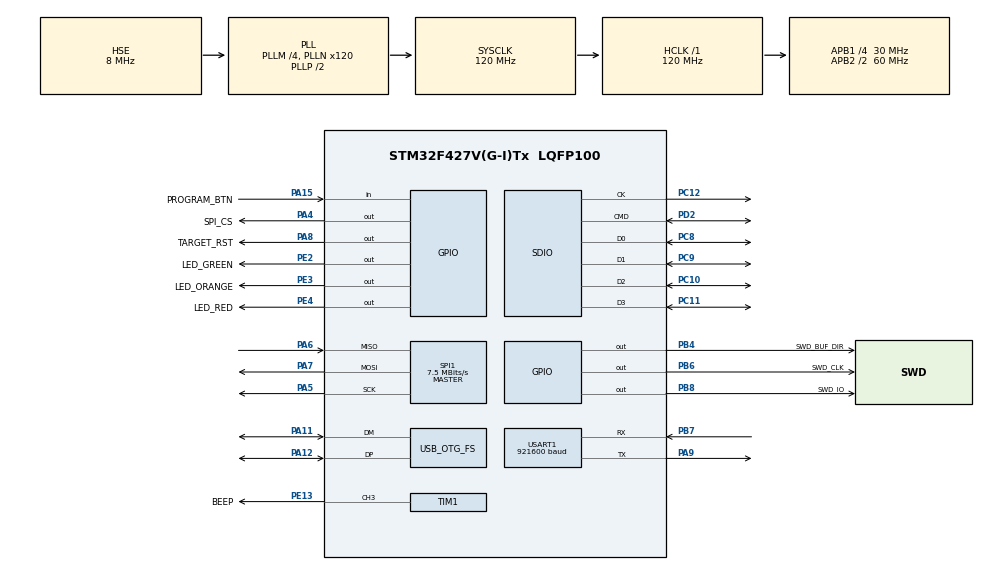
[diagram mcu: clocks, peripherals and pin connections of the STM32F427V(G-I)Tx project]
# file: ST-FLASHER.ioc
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Dma.Request0=SDIO_RX
Dma.Request1=SDIO_TX
Dma.SDIO_RX.0.Direction=DMA_PERIPH_TO_MEMORY
Dma.SDIO_RX.0.FIFOMode=DMA_FIFOMODE_ENABLE
Dma.SDIO_RX.0.FIFOThreshold=DMA_FIFO_THRESHOLD_FULL
Dma.SDIO_RX.0.Instance=DMA2_Stream3
Dma.SDIO_RX.0.MemBurst=DMA_MBURST_INC4
Dma.SDIO_RX.0.MemDataAlignment=DMA_MDATAALIGN_WORD
Dma.SDIO_RX.0.MemInc=DMA_MINC_ENABLE
Dma.SDIO_RX.0.Mode=DMA_PFCTRL
Dma.SDIO_RX.0.PeriphBurst=DMA_PBURST_INC4
Dma.SDIO_RX.0.PeriphDataAlignment=DMA_PDATAALIGN_WORD
Dma.SDIO_RX.0.PeriphInc=DMA_PINC_DISABLE
Dma.SDIO_RX.0.Priority=DMA_PRIORITY_LOW
Dma.SDIO_TX.1.Direction=DMA_MEMORY_TO_PERIPH
Dma.SDIO_TX.1.FIFOMode=DMA_FIFOMODE_ENABLE
Dma.SDIO_TX.1.FIFOThreshold=DMA_FIFO_THRESHOLD_FULL
Dma.SDIO_TX.1.Instance=DMA2_Stream6
Dma.SDIO_TX.1.MemBurst=DMA_MBURST_INC4
Dma.SDIO_TX.1.MemDataAlignment=DMA_MDATAALIGN_WORD
Dma.SDIO_TX.1.MemInc=DMA_MINC_ENABLE
Dma.SDIO_TX.1.Mode=DMA_PFCTRL
Dma.SDIO_TX.1.PeriphBurst=DMA_PBURST_INC4
Dma.SDIO_TX.1.PeriphDataAlignment=DMA_PDATAALIGN_WORD
Dma.SDIO_TX.1.PeriphInc=DMA_PINC_DISABLE
Dma.SDIO_TX.1.Priority=DMA_PRIORITY_LOW
FATFS.USE_DMA_CODE_SD=1
FATFS._FS_TIMEOUT=5000
FATFS._USE_LFN=2
Mcu.Family=STM32F4
Mcu.Name=STM32F427V(G-I)Tx
Mcu.Package=LQFP100
NVIC.DMA2_Stream3_IRQn=true\:6\:0\:true\:false\:true\:false\:true\:true
NVIC.DMA2_Stream6_IRQn=true\:6\:0\:true\:false\:true\:false\:true\:true
NVIC.OTG_FS_IRQn=true\:7\:0\:true\:false\:true\:true\:true\:true
NVIC.PriorityGroup=NVIC_PRIORITYGROUP_4
NVIC.SDIO_IRQn=true\:5\:0\:true\:false\:true\:true\:true\:true
NVIC.TIM1_UP_TIM10_IRQn=true\:0\:0\:false\:false\:true\:true\:true\:true
NVIC.TIM2_IRQn=true\:0\:0\:false\:false\:true\:true\:true\:true
PA11.Mode=Device_Only
PA11.Signal=USB_OTG_FS_DM
PA12.Mode=Device_Only
PA12.Signal=USB_OTG_FS_DP
PA13.Mode=Serial_Wire
PA13.Signal=SYS_JTMS-SWDIO
PA14.Mode=Serial_Wire
PA14.Signal=SYS_JTCK-SWCLK
PA15.GPIO_Label=PROGRAM_BTN
PA15.Signal=GPIO_Input
PA4.GPIO_Label=SPI_CS
PA4.Signal=GPIO_Output
PA5.Mode=Full_Duplex_Master
PA5.Signal=SPI1_SCK
PA6.GPIO_PuPd=GPIO_PULLUP
PA6.Mode=Full_Duplex_Master
PA6.Signal=SPI1_MISO
PA7.Mode=Full_Duplex_Master
PA7.Signal=SPI1_MOSI
PA8.GPIO_Label=TARGET_RST
PA8.Signal=GPIO_Output
PA9.Mode=Asynchronous
PA9.Signal=USART1_TX
PB4.GPIO_Label=SWD_BUF_DIR
PB4.GPIO_PuPd=GPIO_PULLUP
PB4.GPIO_Speed=GPIO_SPEED_FREQ_VERY_HIGH
PB4.Signal=GPIO_Output
PB6.GPIO_Label=SWD_CLK
PB6.GPIO_PuPd=GPIO_PULLDOWN
PB6.GPIO_Speed=GPIO_SPEED_FREQ_VERY_HIGH
PB6.PinState=GPIO_PIN_SET
PB6.Signal=GPIO_Output
PB7.Mode=Asynchronous
PB7.Signal=USART1_RX
PB8.GPIO_Label=SWD_IO
PB8.GPIO_PuPd=GPIO_PULLUP
PB8.GPIO_Speed=GPIO_SPEED_FREQ_VERY_HIGH
PB8.PinState=GPIO_PIN_RESET
PB8.Signal=GPIO_Output
PC10.GPIO_PuPd=GPIO_PULLUP
PC10.Mode=SD_4_bits_Wide_bus
PC10.Signal=SDIO_D2
PC11.GPIO_PuPd=GPIO_PULLUP
PC11.Mode=SD_4_bits_Wide_bus
PC11.Signal=SDIO_D3
PC12.GPIO_PuPd=GPIO_NOPULL
PC12.Mode=SD_4_bits_Wide_bus
PC12.Signal=SDIO_CK
PC8.GPIO_PuPd=GPIO_PULLUP
PC8.Mode=SD_4_bits_Wide_bus
PC8.Signal=SDIO_D0
PC9.GPIO_PuPd=GPIO_PULLUP
PC9.Mode=SD_4_bits_Wide_bus
PC9.Signal=SDIO_D1
PD2.GPIO_PuPd=GPIO_PULLUP
PD2.Mode=SD_4_bits_Wide_bus
PD2.Signal=SDIO_CMD
PE13.GPIO_Label=BEEP
PE13.GPIO_Speed=GPIO_SPEED_FREQ_VERY_HIGH
PE13.Signal=S_TIM1_CH3
PE2.GPIO_Label=LED_GREEN
PE2.PinState=GPIO_PIN_SET
PE2.Signal=GPIO_Output
PE3.GPIO_Label=LED_ORANGE
PE3.PinState=GPIO_PIN_SET
PE3.Signal=GPIO_Output
PE4.GPIO_Label=LED_RED
PE4.PinState=GPIO_PIN_SET
PE4.Signal=GPIO_Output
PH0/OSC_IN.Mode=HSE-External-Oscillator
PH0/OSC_IN.Signal=RCC_OSC_IN
PH1/OSC_OUT.Mode=HSE-External-Oscillator
PH1/OSC_OUT.Signal=RCC_OSC_OUT
ProjectManager.HeapSize=0x2000
ProjectManager.StackSize=0x2000
ProjectManager.TargetToolchain=STM32CubeIDE
RCC.48MHZClocksFreq_Value=48000000
RCC.AHBFreq_Value=120000000
RCC.APB1CLKDivider=RCC_HCLK_DIV4
RCC.APB1Freq_Value=30000000
RCC.APB1TimFreq_Value=60000000
RCC.APB2CLKDivider=RCC_HCLK_DIV2
RCC.APB2Freq_Value=60000000
RCC.APB2TimFreq_Value=120000000
RCC.CortexFreq_Value=120000000
RCC.HCLKFreq_Value=120000000
RCC.HSE_VALUE=8000000
RCC.HSI_VALUE=16000000
RCC.LSE_VALUE=32768
RCC.LockedElements=USBOTGOutput,PeriphPrescOutput,TimPrescOut,APB1Output,APB2Output
RCC.PLLM=4
RCC.PLLN=120
RCC.PLLQ=5
RCC.RCC_RTC_Clock_SourceVirtual=RCC_RTCCLKSOURCE_HSE_DIV8
RCC.RCC_RTC_Clock_Source_FROM_HSE=RCC_RTCCLKSOURCE_HSE_DIV8
RCC.SYSCLKFreq_VALUE=120000000
RCC.SYSCLKSource=RCC_SYSCLKSOURCE_PLLCLK
RCC.VCOOutputFreq_Value=240000000
RTC.AsynchPrediv=127
RTC.SynchPrediv=7874
SH.S_TIM1_CH3.0=TIM1_CH3,PWM Generation3 CH3
SPI1.BaudRatePrescaler=SPI_BAUDRATEPRESCALER_8
SPI1.CalculateBaudRate=7.5 MBits/s
SPI1.Direction=SPI_DIRECTION_2LINES
SPI1.Mode=SPI_MODE_MASTER
SPI1.VirtualType=VM_MASTER
TIM1.Channel-PWM\ Generation3\ CH3=TIM_CHANNEL_3
TIM1.Period=1000
TIM1.Prescaler=120-1
TIM2.Period=65535
TIM2.Prescaler=60-1
USART1.BaudRate=921600
USART1.Mode=MODE_TX
USART1.VirtualMode=VM_ASYNC
USB_DEVICE.CLASS_NAME_FS=MSC
USB_DEVICE.USBD_DEBUG_LEVEL-MSC_FS=3
USB_DEVICE.USBD_SELF_POWERED-MSC_FS=0
USB_DEVICE.VirtualMode-MSC_FS=Msc
USB_DEVICE.VirtualModeFS=Msc_FS
USB_OTG_FS.VirtualMode=Device_Only
VP_FATFS_VS_SDIO.Mode=SDIO
VP_RTC_VS_RTC_Activate.Mode=RTC_Enabled
VP_TIM1_VS_ClockSourceINT.Mode=Internal
VP_TIM2_VS_ClockSourceINT.Mode=Internal
VP_USB_DEVICE_VS_USB_DEVICE_MSC_FS.Mode=MSC_FS
board=custom

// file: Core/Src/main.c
/* USER CODE BEGIN Header */
/**
  ******************************************************************************
  * @file           : main.c
  * @brief          : Main program body
  ******************************************************************************
  * @attention
  *
  * Copyright (c) 2024 STMicroelectronics.
  * All rights reserved.
  *
  * This software is licensed under terms that can be found in the LICENSE file
  * in the root directory of this software component.
  * If no LICENSE file comes with this software, it is provided AS-IS.
  *
  ******************************************************************************
  */
/* USER CODE END Header */
#include "main.h"
#include "fatfs.h"
#include "usb_device.h"

/* USER CODE BEGIN Includes */
#include "Target.h"
#include "led.h"
#include "buzzer.h"

/* USER CODE END Includes */

RTC_HandleTypeDef hrtc;

SD_HandleTypeDef hsd;
DMA_HandleTypeDef hdma_sdio_rx;
DMA_HandleTypeDef hdma_sdio_tx;

SPI_HandleTypeDef hspi1;

TIM_HandleTypeDef htim1;
TIM_HandleTypeDef htim2;

UART_HandleTypeDef huart1;

void SystemClock_Config(void);
static void MX_GPIO_Init(void);
static void MX_DMA_Init(void);
static void MX_SDIO_SD_Init(void);
static void MX_TIM1_Init(void);
static void MX_TIM2_Init(void);
static void MX_SPI1_Init(void);
static void MX_USART1_UART_Init(void);
static void MX_RTC_Init(void);

int main(void)
{

  /* MCU Configuration--------------------------------------------------------*/

  /* Reset of all peripherals, Initializes the Flash interface and the Systick. */
   HAL_Init();

  /* Configure the system clock */
  SystemClock_Config();

  /* Initialize all configured peripherals */
  MX_GPIO_Init();
  MX_DMA_Init();
  MX_SDIO_SD_Init();
  MX_TIM1_Init();
  MX_TIM2_Init();
  MX_SPI1_Init();
  MX_USART1_UART_Init();
  MX_FATFS_Init();
  MX_USB_DEVICE_Init();
  MX_RTC_Init();
  /* USER CODE BEGIN 2 */

	/* SWD DAP usDelay(): TIM1 */
	HAL_TIM_Base_Start(&htim2);

	/* Set programmer LED & Buzzer state */
	LED_SetState(TARGET_LED_STAT_BOOT);
	Buzzer_SetState(BUZZER_BOOT);

	log_message("ST-FLASHER Boot OK! %s\n", PROJECT_VERSION);
	log_message("%s\n", BUILD_INFO);

  /* USER CODE END 2 */

  /* Infinite loop */
  while (1)
  {

    /* USER CODE BEGIN 3 */
  	Target_MainLoop();
  }
  /* USER CODE END 3 */
}

void SystemClock_Config(void)
{
  RCC_OscInitTypeDef RCC_OscInitStruct = {0};
  RCC_ClkInitTypeDef RCC_ClkInitStruct = {0};

  /** Configure the main internal regulator output voltage
  */
  __HAL_RCC_PWR_CLK_ENABLE();
  __HAL_PWR_VOLTAGESCALING_CONFIG(PWR_REGULATOR_VOLTAGE_SCALE3);

  /** Initializes the RCC Oscillators according to the specified parameters
  * in the RCC_OscInitTypeDef structure.
  */
  RCC_OscInitStruct.OscillatorType = RCC_OSCILLATORTYPE_HSE;
  RCC_OscInitStruct.HSEState = RCC_HSE_ON;
  RCC_OscInitStruct.PLL.PLLState = RCC_PLL_ON;
  RCC_OscInitStruct.PLL.PLLSource = RCC_PLLSOURCE_HSE;
  RCC_OscInitStruct.PLL.PLLM = 4;
  RCC_OscInitStruct.PLL.PLLN = 120;
  RCC_OscInitStruct.PLL.PLLP = RCC_PLLP_DIV2;
  RCC_OscInitStruct.PLL.PLLQ = 5;
  if (HAL_RCC_OscConfig(&RCC_OscInitStruct) != HAL_OK)
  {
    Error_Handler();
  }

  /** Initializes the CPU, AHB and APB buses clocks
  */
  RCC_ClkInitStruct.ClockType = RCC_CLOCKTYPE_HCLK|RCC_CLOCKTYPE_SYSCLK
                              |RCC_CLOCKTYPE_PCLK1|RCC_CLOCKTYPE_PCLK2;
  RCC_ClkInitStruct.SYSCLKSource = RCC_SYSCLKSOURCE_PLLCLK;
  RCC_ClkInitStruct.AHBCLKDivider = RCC_SYSCLK_DIV1;
  RCC_ClkInitStruct.APB1CLKDivider = RCC_HCLK_DIV4;
  RCC_ClkInitStruct.APB2CLKDivider = RCC_HCLK_DIV2;

  if (HAL_RCC_ClockConfig(&RCC_ClkInitStruct, FLASH_LATENCY_3) != HAL_OK)
  {
    Error_Handler();
  }
}

static void MX_RTC_Init(void)
{

  /** Initialize RTC Only
  */
  hrtc.Instance = RTC;
  hrtc.Init.HourFormat = RTC_HOURFORMAT_24;
  hrtc.Init.AsynchPrediv = 127;
  hrtc.Init.SynchPrediv = 7874;
  hrtc.Init.OutPut = RTC_OUTPUT_DISABLE;
  hrtc.Init.OutPutPolarity = RTC_OUTPUT_POLARITY_HIGH;
  hrtc.Init.OutPutType = RTC_OUTPUT_TYPE_OPENDRAIN;
  if (HAL_RTC_Init(&hrtc) != HAL_OK)
  {
    Error_Handler();
  }

}

static void MX_SDIO_SD_Init(void)
{

  hsd.Instance = SDIO;
  hsd.Init.ClockEdge = SDIO_CLOCK_EDGE_RISING;
  hsd.Init.ClockBypass = SDIO_CLOCK_BYPASS_DISABLE;
  hsd.Init.ClockPowerSave = SDIO_CLOCK_POWER_SAVE_DISABLE;
  hsd.Init.BusWide = SDIO_BUS_WIDE_4B;
  hsd.Init.HardwareFlowControl = SDIO_HARDWARE_FLOW_CONTROL_DISABLE;
  hsd.Init.ClockDiv = 0;
  /* USER CODE BEGIN SDIO_Init 2 */

  /* I don't know why... */
  hsd.Init.BusWide = SDIO_BUS_WIDE_1B;

  /* USER CODE END SDIO_Init 2 */

}

static void MX_SPI1_Init(void)
{

  /* SPI1 parameter configuration*/
  hspi1.Instance = SPI1;
  hspi1.Init.Mode = SPI_MODE_MASTER;
  hspi1.Init.Direction = SPI_DIRECTION_2LINES;
  hspi1.Init.DataSize = SPI_DATASIZE_8BIT;
  hspi1.Init.CLKPolarity = SPI_POLARITY_LOW;
  hspi1.Init.CLKPhase = SPI_PHASE_1EDGE;
  hspi1.Init.NSS = SPI_NSS_SOFT;
  hspi1.Init.BaudRatePrescaler = SPI_BAUDRATEPRESCALER_8;
  hspi1.Init.FirstBit = SPI_FIRSTBIT_MSB;
  hspi1.Init.TIMode = SPI_TIMODE_DISABLE;
  hspi1.Init.CRCCalculation = SPI_CRCCALCULATION_DISABLE;
  hspi1.Init.CRCPolynomial = 10;
  if (HAL_SPI_Init(&hspi1) != HAL_OK)
  {
    Error_Handler();
  }

}

static void MX_TIM1_Init(void)
{

  TIM_ClockConfigTypeDef sClockSourceConfig = {0};
  TIM_MasterConfigTypeDef sMasterConfig = {0};
  TIM_OC_InitTypeDef sConfigOC = {0};
  TIM_BreakDeadTimeConfigTypeDef sBreakDeadTimeConfig = {0};

  htim1.Instance = TIM1;
  htim1.Init.Prescaler = 120-1;
  htim1.Init.CounterMode = TIM_COUNTERMODE_UP;
  htim1.Init.Period = 1000;
  htim1.Init.ClockDivision = TIM_CLOCKDIVISION_DIV1;
  htim1.Init.RepetitionCounter = 0;
  htim1.Init.AutoReloadPreload = TIM_AUTORELOAD_PRELOAD_DISABLE;
  if (HAL_TIM_Base_Init(&htim1) != HAL_OK)
  {
    Error_Handler();
  }
  sClockSourceConfig.ClockSource = TIM_CLOCKSOURCE_INTERNAL;
  if (HAL_TIM_ConfigClockSource(&htim1, &sClockSourceConfig) != HAL_OK)
  {
    Error_Handler();
  }
  if (HAL_TIM_PWM_Init(&htim1) != HAL_OK)
  {
    Error_Handler();
  }
  sMasterConfig.MasterOutputTrigger = TIM_TRGO_RESET;
  sMasterConfig.MasterSlaveMode = TIM_MASTERSLAVEMODE_DISABLE;
  if (HAL_TIMEx_MasterConfigSynchronization(&htim1, &sMasterConfig) != HAL_OK)
  {
    Error_Handler();
  }
  sConfigOC.OCMode = TIM_OCMODE_PWM1;
  sConfigOC.Pulse = 0;
  sConfigOC.OCPolarity = TIM_OCPOLARITY_HIGH;
  sConfigOC.OCNPolarity = TIM_OCNPOLARITY_HIGH;
  sConfigOC.OCFastMode = TIM_OCFAST_DISABLE;
  sConfigOC.OCIdleState = TIM_OCIDLESTATE_RESET;
  sConfigOC.OCNIdleState = TIM_OCNIDLESTATE_RESET;
  if (HAL_TIM_PWM_ConfigChannel(&htim1, &sConfigOC, TIM_CHANNEL_3) != HAL_OK)
  {
    Error_Handler();
  }
  sBreakDeadTimeConfig.OffStateRunMode = TIM_OSSR_DISABLE;
  sBreakDeadTimeConfig.OffStateIDLEMode = TIM_OSSI_DISABLE;
  sBreakDeadTimeConfig.LockLevel = TIM_LOCKLEVEL_OFF;
  sBreakDeadTimeConfig.DeadTime = 0;
  sBreakDeadTimeConfig.BreakState = TIM_BREAK_DISABLE;
  sBreakDeadTimeConfig.BreakPolarity = TIM_BREAKPOLARITY_HIGH;
  sBreakDeadTimeConfig.AutomaticOutput = TIM_AUTOMATICOUTPUT_DISABLE;
  if (HAL_TIMEx_ConfigBreakDeadTime(&htim1, &sBreakDeadTimeConfig) != HAL_OK)
  {
    Error_Handler();
  }
  HAL_TIM_MspPostInit(&htim1);

}

static void MX_TIM2_Init(void)
{

  TIM_ClockConfigTypeDef sClockSourceConfig = {0};
  TIM_MasterConfigTypeDef sMasterConfig = {0};

  htim2.Instance = TIM2;
  htim2.Init.Prescaler = 60-1;
  htim2.Init.CounterMode = TIM_COUNTERMODE_UP;
  htim2.Init.Period = 65535;
  htim2.Init.ClockDivision = TIM_CLOCKDIVISION_DIV1;
  htim2.Init.AutoReloadPreload = TIM_AUTORELOAD_PRELOAD_DISABLE;
  if (HAL_TIM_Base_Init(&htim2) != HAL_OK)
  {
    Error_Handler();
  }
  sClockSourceConfig.ClockSource = TIM_CLOCKSOURCE_INTERNAL;
  if (HAL_TIM_ConfigClockSource(&htim2, &sClockSourceConfig) != HAL_OK)
  {
    Error_Handler();
  }
  sMasterConfig.MasterOutputTrigger = TIM_TRGO_RESET;
  sMasterConfig.MasterSlaveMode = TIM_MASTERSLAVEMODE_DISABLE;
  if (HAL_TIMEx_MasterConfigSynchronization(&htim2, &sMasterConfig) != HAL_OK)
  {
    Error_Handler();
  }

}

static void MX_USART1_UART_Init(void)
{

  huart1.Instance = USART1;
  huart1.Init.BaudRate = 921600;
  huart1.Init.WordLength = UART_WORDLENGTH_8B;
  huart1.Init.StopBits = UART_STOPBITS_1;
  huart1.Init.Parity = UART_PARITY_NONE;
  huart1.Init.Mode = UART_MODE_TX;
  huart1.Init.HwFlowCtl = UART_HWCONTROL_NONE;
  huart1.Init.OverSampling = UART_OVERSAMPLING_16;
  if (HAL_UART_Init(&huart1) != HAL_OK)
  {
    Error_Handler();
  }

}

static void MX_DMA_Init(void)
{

  /* DMA controller clock enable */
  __HAL_RCC_DMA2_CLK_ENABLE();

  /* DMA interrupt init */
  /* DMA2_Stream3_IRQn interrupt configuration */
  HAL_NVIC_SetPriority(DMA2_Stream3_IRQn, 6, 0);
  HAL_NVIC_EnableIRQ(DMA2_Stream3_IRQn);
  /* DMA2_Stream6_IRQn interrupt configuration */
  HAL_NVIC_SetPriority(DMA2_Stream6_IRQn, 6, 0);
  HAL_NVIC_EnableIRQ(DMA2_Stream6_IRQn);

}

static void MX_GPIO_Init(void)
{
  GPIO_InitTypeDef GPIO_InitStruct = {0};

  /* GPIO Ports Clock Enable */
  __HAL_RCC_GPIOE_CLK_ENABLE();
  __HAL_RCC_GPIOH_CLK_ENABLE();
  __HAL_RCC_GPIOA_CLK_ENABLE();
  __HAL_RCC_GPIOC_CLK_ENABLE();
  __HAL_RCC_GPIOD_CLK_ENABLE();
  __HAL_RCC_GPIOB_CLK_ENABLE();

  /*Configure GPIO pin Output Level */
  HAL_GPIO_WritePin(GPIOE, LED_GREEN_Pin|LED_ORANGE_Pin|LED_RED_Pin, GPIO_PIN_SET);

  /*Configure GPIO pin Output Level */
  HAL_GPIO_WritePin(GPIOA, SPI_CS_Pin|TARGET_RST_Pin, GPIO_PIN_RESET);

  /*Configure GPIO pin Output Level */
  HAL_GPIO_WritePin(GPIOB, SWD_BUF_DIR_Pin|SWD_IO_Pin, GPIO_PIN_RESET);

  /*Configure GPIO pin Output Level */
  HAL_GPIO_WritePin(SWD_CLK_GPIO_Port, SWD_CLK_Pin, GPIO_PIN_SET);

  /*Configure GPIO pins : LED_GREEN_Pin LED_ORANGE_Pin LED_RED_Pin */
  GPIO_InitStruct.Pin = LED_GREEN_Pin|LED_ORANGE_Pin|LED_RED_Pin;
  GPIO_InitStruct.Mode = GPIO_MODE_OUTPUT_PP;
  GPIO_InitStruct.Pull = GPIO_NOPULL;
  GPIO_InitStruct.Speed = GPIO_SPEED_FREQ_LOW;
  HAL_GPIO_Init(GPIOE, &GPIO_InitStruct);

  /*Configure GPIO pins : SPI_CS_Pin TARGET_RST_Pin */
  GPIO_InitStruct.Pin = SPI_CS_Pin|TARGET_RST_Pin;
  GPIO_InitStruct.Mode = GPIO_MODE_OUTPUT_PP;
  GPIO_InitStruct.Pull = GPIO_NOPULL;
  GPIO_InitStruct.Speed = GPIO_SPEED_FREQ_LOW;
  HAL_GPIO_Init(GPIOA, &GPIO_InitStruct);

  /*Configure GPIO pin : PROGRAM_BTN_Pin */
  GPIO_InitStruct.Pin = PROGRAM_BTN_Pin;
  GPIO_InitStruct.Mode = GPIO_MODE_INPUT;
  GPIO_InitStruct.Pull = GPIO_NOPULL;
  HAL_GPIO_Init(PROGRAM_BTN_GPIO_Port, &GPIO_InitStruct);

  /*Configure GPIO pins : SWD_BUF_DIR_Pin SWD_IO_Pin */
  GPIO_InitStruct.Pin = SWD_BUF_DIR_Pin|SWD_IO_Pin;
  GPIO_InitStruct.Mode = GPIO_MODE_OUTPUT_PP;
  GPIO_InitStruct.Pull = GPIO_PULLUP;
  GPIO_InitStruct.Speed = GPIO_SPEED_FREQ_VERY_HIGH;
  HAL_GPIO_Init(GPIOB, &GPIO_InitStruct);

  /*Configure GPIO pin : SWD_CLK_Pin */
  GPIO_InitStruct.Pin = SWD_CLK_Pin;
  GPIO_InitStruct.Mode = GPIO_MODE_OUTPUT_PP;
  GPIO_InitStruct.Pull = GPIO_PULLDOWN;
  GPIO_InitStruct.Speed = GPIO_SPEED_FREQ_VERY_HIGH;
  HAL_GPIO_Init(SWD_CLK_GPIO_Port, &GPIO_InitStruct);

}

void Error_Handler(void)
{
  /* USER CODE BEGIN Error_Handler_Debug */
	printf("Error_Handle()\n");
  /* User can add his own implementation to report the HAL error return state */
  __disable_irq();
  while (1)
  {
  }
  /* USER CODE END Error_Handler_Debug */
}
